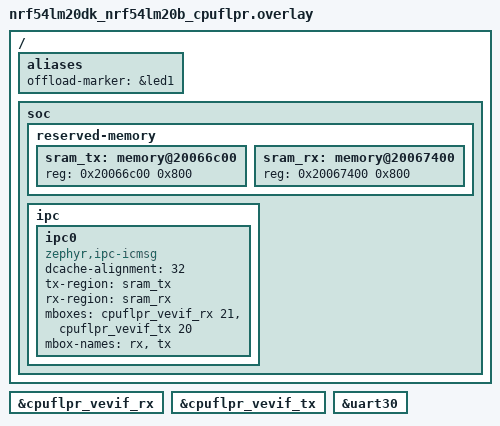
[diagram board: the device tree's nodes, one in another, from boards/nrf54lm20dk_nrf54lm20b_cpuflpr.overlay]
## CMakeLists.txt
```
#
# Copyright (c) 2026 Nordic Semiconductor ASA
#
# SPDX-License-Identifier: LicenseRef-Nordic-5-Clause
#

cmake_minimum_required(VERSION 3.20.0)

find_package(Zephyr REQUIRED HINTS $ENV{ZEPHYR_BASE})
project(flpr_offload_remote)

# The transport to the M33 is the only FLPR-specific source. The workload (the
# peripheral backend, the batch loop and the processing) comes from the same
# file the M33 uses in the local baseline.
target_sources(app PRIVATE src/main.c)
include(${CMAKE_CURRENT_SOURCE_DIR}/../common/workload.cmake)
```

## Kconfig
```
#
# Copyright (c) 2026 Nordic Semiconductor ASA
#
# SPDX-License-Identifier: LicenseRef-Nordic-5-Clause
#

# Application Kconfig for the FLPR (remote) image. The two images have separate
# Kconfig scopes; the workload selection is defined once in
# common/Kconfig.workload and sysbuild.cmake sets it on both.

menu "FLPR offload workload"
rsource "../common/Kconfig.workload"
endmenu

source "Kconfig.zephyr"
```

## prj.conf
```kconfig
# Copyright (c) 2026 Nordic Semiconductor ASA
# SPDX-License-Identifier: LicenseRef-Nordic-5-Clause

CONFIG_LOG=y
CONFIG_GPIO=y

# Inter-core transport (ICMsg over the shared-memory region in the overlay).
CONFIG_IPC_SERVICE=y
CONFIG_MBOX=y
CONFIG_HEAP_MEM_POOL_SIZE=2048

# The workload's peripheral driver runs here, on the FLPR, and not on the M33. Its
# Kconfig is not in this file: sysbuild.cmake adds peripherals/<name>/poll.conf or
# irq.conf to this image.

CONFIG_PM=n
```

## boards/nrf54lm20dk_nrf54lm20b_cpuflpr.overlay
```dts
/*
 * Copyright (c) 2026 Nordic Semiconductor ASA
 *
 * SPDX-License-Identifier: LicenseRef-Nordic-5-Clause
 */

/*
 * FLPR side of the transport. The two shared-memory regions are the same
 * physical addresses as on the M33 with tx and rx swapped: this core writes
 * where the M33 reads and reads where the M33 writes.
 *
 * Nothing here depends on the peripheral. sysbuild.cmake adds
 * peripherals/<name>/peripheral.overlay to this image, the same overlay the M33
 * gets in the local baseline; only the owning core differs.
 */

/ {
	aliases {
		offload-marker = &led1;
	};

	soc {
		reserved-memory {
			#address-cells = <1>;
			#size-cells = <1>;

			sram_tx: memory@20066c00 {
				reg = <0x20066c00 0x800>;
			};

			sram_rx: memory@20067400 {
				reg = <0x20067400 0x800>;
			};
		};

		ipc {
			ipc0: ipc0 {
				compatible = "zephyr,ipc-icmsg";
				dcache-alignment = <32>;
				tx-region = <&sram_tx>;
				rx-region = <&sram_rx>;
				mboxes = <&cpuflpr_vevif_rx 21>, <&cpuflpr_vevif_tx 20>;
				mbox-names = "rx", "tx";
				status = "okay";
			};
		};
	};
};

&cpuflpr_vevif_rx {
	status = "okay";
};

&cpuflpr_vevif_tx {
	status = "okay";
};

&uart30 {
	/delete-property/ hw-flow-control;
};
```

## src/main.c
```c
/*
 * Copyright (c) 2026 Nordic Semiconductor ASA
 *
 * SPDX-License-Identifier: LicenseRef-Nordic-5-Clause
 */

/*
 * FLPR image. It holds only the transport to the M33: the workload itself (the
 * peripheral backend, the batch loop and the processing) is the same code the M33
 * runs in the local baseline, selected at build time by -DOFFLOAD_PERIPHERAL and
 * -DOFFLOAD_TRIGGER. Nothing in this file changes with the peripheral or the
 * trigger.
 */

#include <string.h>

#include <zephyr/kernel.h>
#include <zephyr/ipc/ipc_service.h>
#include <zephyr/logging/log.h>

#include "offload_protocol.h"
#include "workload.h"
#include "workload_loop.h"
#include "app_metrics.h"

LOG_MODULE_REGISTER(flpr, LOG_LEVEL_INF);

static const struct device *const ipc0 = DEVICE_DT_GET(DT_NODELABEL(ipc0));
static struct ipc_ept ep;
static K_SEM_DEFINE(bound_sem, 0, 1);
static K_SEM_DEFINE(control_sem, 0, 1);

static struct offload_control control;

static void ep_bound(void *priv)
{
	k_sem_give(&bound_sem);
}

static void ep_recv(const void *data, size_t len, void *priv)
{
	const struct offload_msg *msg = data;

	if (len != sizeof(*msg)) {
		return;
	}

	if (msg->type == OFFLOAD_MSG_CONTROL) {
		control = msg->control;
		k_sem_give(&control_sem);
	}
}

static int send_msg(const struct offload_msg *msg)
{
	while (true) {
		int ret = ipc_service_send(&ep, msg, sizeof(*msg));

		if (ret >= 0) {
			return 0;
		}
		if (ret != -ENOMEM) {
			return ret;
		}
		/* The M33 has not drained the shared buffer yet. Sleep rather than spin,
		 * so lower-priority threads (logging) still run.
		 */
		k_msleep(1);
	}
}

static int send_status(uint32_t status)
{
	const struct offload_msg msg = {
		.type = OFFLOAD_MSG_STATUS,
		.status = status,
	};

	return send_msg(&msg);
}

static void send_error(int error)
{
	const struct offload_msg msg = {
		.type = OFFLOAD_MSG_ERROR,
		.error = error,
	};

	(void)send_msg(&msg);
}

/* The loop hands each result here; it goes to the M33 as one RESULT message. */
static int emit(uint32_t seq, const void *result, size_t len, uint32_t acquire_us,
		uint32_t process_us)
{
	struct offload_msg msg = {
		.type = OFFLOAD_MSG_RESULT,
		.result = {
			.iteration = seq,
			.acquire_us = acquire_us,
			.process_us = process_us,
			.len = (uint16_t)len,
		},
	};

	memcpy(msg.result.bytes, result, len);
	return send_msg(&msg);
}

int main(void)
{
	static struct ipc_ept_cfg ep_cfg = {
		.name = "offload",
		.cb = {
			.bound = ep_bound,
			.received = ep_recv,
		},
	};
	int ret;

	marker_init();

	ret = ipc_service_open_instance(ipc0);
	if (ret < 0 && ret != -EALREADY) {
		return ret;
	}

	ret = ipc_service_register_endpoint(ipc0, &ep, &ep_cfg);
	if (ret < 0) {
		return ret;
	}

	k_sem_take(&bound_sem, K_FOREVER);
	LOG_INF("endpoint bound, waiting for control");

	k_sem_take(&control_sem, K_FOREVER);

	ret = workload_init();
	if (ret < 0) {
		send_error(ret);
		return ret;
	}

	LOG_INF("workload %s, %s trigger", CONFIG_APP_PERIPHERAL,
		IS_ENABLED(CONFIG_APP_TRIGGER_INTERRUPT) ? "interrupt" : "timer");
	(void)send_status(OFFLOAD_STATUS_RUNNING);

	ret = workload_loop(control.iterations, control.sample_interval_ms, emit);
	if (ret < 0) {
		send_error(ret);
		return ret;
	}

	(void)send_status(OFFLOAD_STATUS_DONE);
	LOG_INF("run complete");
	return 0;
}
```
